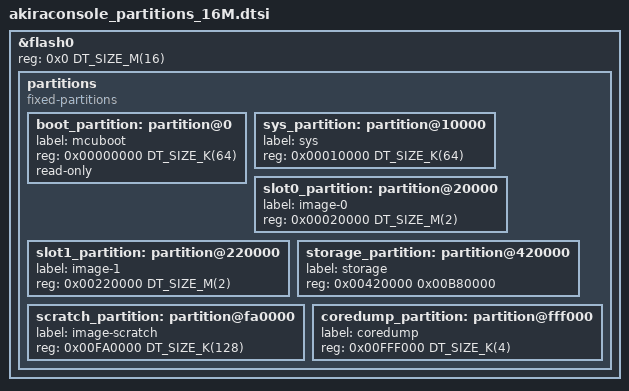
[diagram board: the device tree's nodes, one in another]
/*
 * AkiraConsole — 16 MB flash partition table (MCUboot, 2 MB image slots)
 *
 * Flash layout (16 MB = 0x1000000):
 *
 *   0x000000  boot_partition   (mcuboot)    64 KB
 *   0x010000  sys_partition    (sys)        64 KB
 *   0x020000  slot0_partition  (image-0)     2 MB
 *   0x220000  slot1_partition  (image-1)     2 MB
 *   0x420000  storage_partition             11.5 MB
 *   0xFA0000  scratch_partition (swap)      128 KB
 *   0xFFF000  coredump_partition              4 KB
 *
 * SPDX-License-Identifier: Apache-2.0
 */

/* Override flash size: hardware uses 16 MB, base dtsi declares 8 MB */
&flash0 {
	reg = <0x0 DT_SIZE_M(16)>;

	partitions {
		compatible = "fixed-partitions";
		#address-cells = <1>;
		#size-cells = <1>;

		boot_partition: partition@0 {
			label = "mcuboot";
			reg = <0x00000000 DT_SIZE_K(64)>;
			read-only;
		};

		sys_partition: partition@10000 {
			label = "sys";
			reg = <0x00010000 DT_SIZE_K(64)>;
		};

		slot0_partition: partition@20000 {
			label = "image-0";
			reg = <0x00020000 DT_SIZE_M(2)>;
		};

		slot1_partition: partition@220000 {
			label = "image-1";
			reg = <0x00220000 DT_SIZE_M(2)>;
		};

		storage_partition: partition@420000 {
			label = "storage";
			reg = <0x00420000 0x00B80000>; /* 11.5 MB */
		};

		scratch_partition: partition@fa0000 {
			label = "image-scratch";
			reg = <0x00FA0000 DT_SIZE_K(128)>;
		};

		coredump_partition: partition@fff000 {
			label = "coredump";
			reg = <0x00FFF000 DT_SIZE_K(4)>;
		};
	};
};
